# nrf9220_cellrf register map
Vendor: Nordic Semiconductor; Series: nRF92; File version: 1
CPU: CM0 r0p0, little endian, no MPU, no FPU, 2 interrupt priority bits, 33 interrupts
Registers are 32-bit, read-write, reset 0x0 unless marked. A register's access mark holds for its fields unless they carry their own. Offsets are from the block's base; [hi:lo] are bit positions; {n}, {i} and the like mark numbered series; 'fields as' and 'values as' point back to an identical list.

## TXDFE — HALTI_TX_register_map AhmaTxDigDigitalReg register map KarhuTxDigAnalogReg register map
Base 0x46120000
0x00 TASKS_TX_START_DIG wo — Starts TX digital core.
  [0] TASKS_TX_START_DIG
    1=Trigger task
0x04 TASKS_TX_STOP_DIG wo — Stops TX digital core.
  [0] TASKS_TX_STOP_DIG
    1=Trigger task
0x08 TASKS_TX_COMPARATOR wo — Reset comparator status register
  [0] TASKS_TX_COMPARATOR
    1=Trigger task
0x0C TASKS_TX_SATURATION_HOLD wo — Reset saturation hold
  [0] TASKS_TX_SATURATION_HOLD
    1=Trigger task
0x10 TASKS_TX_CLEAR_UNDERFLOW wo — Clear FIFO underflow bit
  [0] TASKS_TX_CLEAR_UNDERFLOW
    1=Trigger task
0x14 TASKS_TX_CAPT_SAMPLE_CNT wo — Capture sample counter value to register
  [0] TASKS_TX_CAPT_SAMPLE_CNT
    1=Trigger task
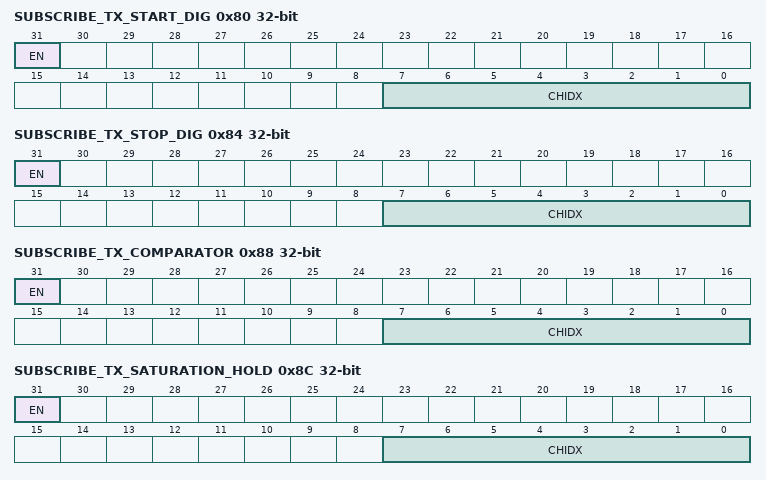
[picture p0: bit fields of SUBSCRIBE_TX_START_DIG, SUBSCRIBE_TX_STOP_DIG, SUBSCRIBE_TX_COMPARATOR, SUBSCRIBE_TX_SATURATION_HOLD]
0x80 SUBSCRIBE_TX_START_DIG — Subscribe configuration for task TX_START_DIG
  [31] EN
    0=Disabled (Disable subscription); 1=Enabled (Enable subscription)
  [7:0] CHIDX — DPPI channel that task TX_START_DIG will subscribe to
0x84 SUBSCRIBE_TX_STOP_DIG — Subscribe configuration for task TX_STOP_DIG
  [31] EN
    values as SUBSCRIBE_TX_START_DIG.EN
  [7:0] CHIDX — DPPI channel that task TX_STOP_DIG will subscribe to
0x88 SUBSCRIBE_TX_COMPARATOR — Subscribe configuration for task TX_COMPARATOR
  [31] EN
    values as SUBSCRIBE_TX_START_DIG.EN
  [7:0] CHIDX — DPPI channel that task TX_COMPARATOR will subscribe to
0x8C SUBSCRIBE_TX_SATURATION_HOLD — Subscribe configuration for task TX_SATURATION_HOLD
  [31] EN
    values as SUBSCRIBE_TX_START_DIG.EN
  [7:0] CHIDX — DPPI channel that task TX_SATURATION_HOLD will subscribe to
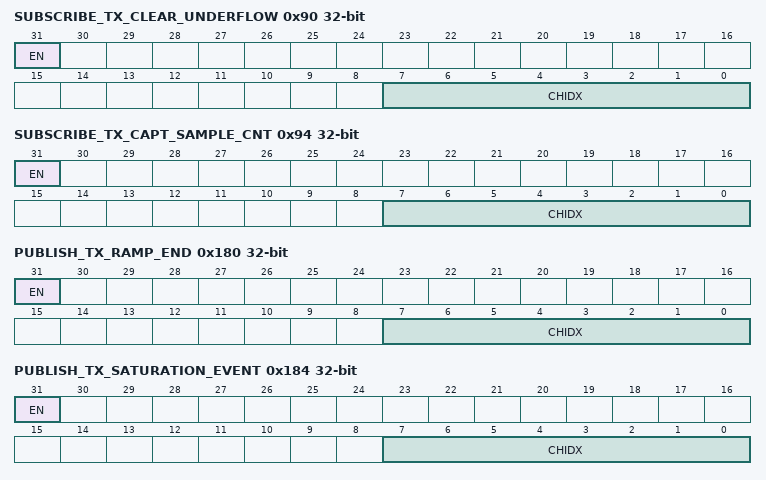
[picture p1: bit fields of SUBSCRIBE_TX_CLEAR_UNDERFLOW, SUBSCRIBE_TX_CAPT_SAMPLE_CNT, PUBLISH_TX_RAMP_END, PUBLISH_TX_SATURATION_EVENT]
0x90 SUBSCRIBE_TX_CLEAR_UNDERFLOW — Subscribe configuration for task TX_CLEAR_UNDERFLOW
  [31] EN
    values as SUBSCRIBE_TX_START_DIG.EN
  [7:0] CHIDX — DPPI channel that task TX_CLEAR_UNDERFLOW will subscribe to
0x94 SUBSCRIBE_TX_CAPT_SAMPLE_CNT — Subscribe configuration for task TX_CAPT_SAMPLE_CNT
  [31] EN
    values as SUBSCRIBE_TX_START_DIG.EN
  [7:0] CHIDX — DPPI channel that task TX_CAPT_SAMPLE_CNT will subscribe to
0x100 EVENTS_TX_RAMP_END — Ramp generator reached end.
  [0] EVENTS_TX_RAMP_END
    0=NotGenerated (Event not generated); 1=Generated (Event generated)
0x104 EVENTS_TX_SATURATION_EVENT — Indicates when saturation is occurred
  [0] EVENTS_TX_SATURATION_EVENT
    values as EVENTS_TX_RAMP_END.EVENTS_TX_RAMP_END
0x108 EVENTS_TX_SATURATION_EVENT_N — Indicates when saturation is ended
  [0] EVENTS_TX_SATURATION_EVENT_N
    values as EVENTS_TX_RAMP_END.EVENTS_TX_RAMP_END
0x10C EVENTS_TX_FIFO_UNDERFLOW — Indicates if FIFO goes to underflow state
  [0] EVENTS_TX_FIFO_UNDERFLOW
    values as EVENTS_TX_RAMP_END.EVENTS_TX_RAMP_END
0x180 PUBLISH_TX_RAMP_END — Publish configuration for event TX_RAMP_END
  [31] EN
    0=Disabled (Disable publishing); 1=Enabled (Enable publishing)
  [7:0] CHIDX — DPPI channel that event TX_RAMP_END will publish to
0x184 PUBLISH_TX_SATURATION_EVENT — Publish configuration for event TX_SATURATION_EVENT
  [31] EN
    values as PUBLISH_TX_RAMP_END.EN
  [7:0] CHIDX — DPPI channel that event TX_SATURATION_EVENT will publish to
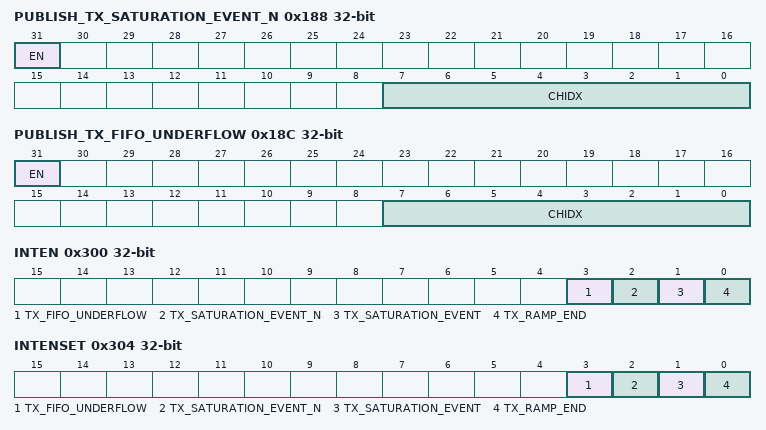
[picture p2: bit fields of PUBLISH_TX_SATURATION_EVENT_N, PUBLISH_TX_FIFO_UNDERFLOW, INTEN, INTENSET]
0x188 PUBLISH_TX_SATURATION_EVENT_N — Publish configuration for event TX_SATURATION_EVENT_N
  [31] EN
    values as PUBLISH_TX_RAMP_END.EN
  [7:0] CHIDX — DPPI channel that event TX_SATURATION_EVENT_N will publish to
0x18C PUBLISH_TX_FIFO_UNDERFLOW — Publish configuration for event TX_FIFO_UNDERFLOW
  [31] EN
    values as PUBLISH_TX_RAMP_END.EN
  [7:0] CHIDX — DPPI channel that event TX_FIFO_UNDERFLOW will publish to
0x300 INTEN — Enable or disable interrupt
  [all] fields
    0=Disabled; 1=Enabled
  [3] TX_FIFO_UNDERFLOW — Enable or disable interrupt for event TX_FIFO_UNDERFLOW
  [2] TX_SATURATION_EVENT_N — Enable or disable interrupt for event TX_SATURATION_EVENT_N
  [1] TX_SATURATION_EVENT — Enable or disable interrupt for event TX_SATURATION_EVENT
  [0] TX_RAMP_END — Enable or disable interrupt for event TX_RAMP_END
0x304 INTENSET — Enable interrupt
  [all] fields
    on read: 0=Disabled (Read: Disabled); 1=Enabled (Read: Enabled) | on write: 1=Set (Enable)
  [3] TX_FIFO_UNDERFLOW — Write '1' to enable interrupt for event TX_FIFO_UNDERFLOW
  [2] TX_SATURATION_EVENT_N — Write '1' to enable interrupt for event TX_SATURATION_EVENT_N
  [1] TX_SATURATION_EVENT — Write '1' to enable interrupt for event TX_SATURATION_EVENT
  [0] TX_RAMP_END — Write '1' to enable interrupt for event TX_RAMP_END
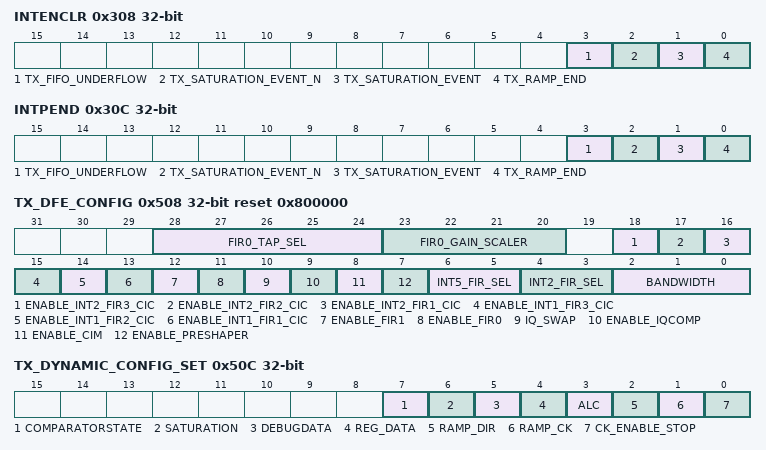
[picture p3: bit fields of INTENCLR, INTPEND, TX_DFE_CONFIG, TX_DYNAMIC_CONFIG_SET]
0x308 INTENCLR — Disable interrupt
  [all] fields
    on read: 0=Disabled (Read: Disabled); 1=Enabled (Read: Enabled) | on write: 1=Clear (Disable)
  [3] TX_FIFO_UNDERFLOW — Write '1' to disable interrupt for event TX_FIFO_UNDERFLOW
  [2] TX_SATURATION_EVENT_N — Write '1' to disable interrupt for event TX_SATURATION_EVENT_N
  [1] TX_SATURATION_EVENT — Write '1' to disable interrupt for event TX_SATURATION_EVENT
  [0] TX_RAMP_END — Write '1' to disable interrupt for event TX_RAMP_END
0x30C INTPEND ro — Pending interrupts
  [all] fields
    on read: 0=NotPending (Read: Not pending); 1=Pending (Read: Pending)
  [3] TX_FIFO_UNDERFLOW — Read pending status of interrupt for event TX_FIFO_UNDERFLOW
  [2] TX_SATURATION_EVENT_N — Read pending status of interrupt for event TX_SATURATION_EVENT_N
  [1] TX_SATURATION_EVENT — Read pending status of interrupt for event TX_SATURATION_EVENT
  [0] TX_RAMP_END — Read pending status of interrupt for event TX_RAMP_END
0x500 TX_DIG_ENABLE — TX digital enable
  [0] ENABLE — Enable TX digital. When enabled the task TASKS_TX_DIG_START can be used to activate TX digital.
    0=Disabled; 1=Enabled
0x504 TX_FIFO_ENABLE
  [0] ENABLE — Enable TX FIFO. When enabled the task TASKS_TX_FIFO_START can be used to activate TX FIFO.
    0=Disabled; 1=Enabled
0x508 TX_DFE_CONFIG reset 0x800000 — TX DFE datapath configuration
  [28:24] FIR0_TAP_SEL — Selects how many taps there is in use in FIR0. 2-28 will give corresponding numbers of taps. Other values will take all taps into use.
  [23:20] FIR0_GAIN_SCALER — Gain scaling after FIR0. Number indicates how many times data value is shifted to right after FIR0.
  [18] ENABLE_INT2_FIR3_CIC — Enable or disable first CIC after INT2FIR3
    0=Disabled; 1=Enabled
  [17] ENABLE_INT2_FIR2_CIC — Enable or disable first CIC after INT2FIR2
    0=Disabled; 1=Enabled
  [16] ENABLE_INT2_FIR1_CIC — Enable or disable first CIC after INT2FIR1
    0=Disabled; 1=Enabled
  [15] ENABLE_INT1_FIR3_CIC — Enable or disable first CIC after INT1FIR3
    0=Disabled; 1=Enabled
  [14] ENABLE_INT1_FIR2_CIC — Enable or disable first CIC after INT1FIR2
    0=Disabled; 1=Enabled
  [13] ENABLE_INT1_FIR1_CIC — Enable or disable first CIC after INT1FIR1
    0=Disabled; 1=Enabled
  [12] ENABLE_FIR1 — Enable or disable second configurable FIR.
    0=Disabled; 1=Enabled
  [11] ENABLE_FIR0 — Enable or disable first configurable FIR.
    0=Disabled; 1=Enabled
  [10] IQ_SWAP — I and Q branches are swapped at the input.
    0=Disabled; 1=Enabled
  [9] ENABLE_IQCOMP — IQ compensation enabled in TX datapath.
    0=Disabled; 1=Enabled
  [8] ENABLE_CIM — CIM enabled in TX datapath.
    0=Disabled; 1=Enabled
  [7] ENABLE_PRESHAPER — Preshaper enabled in TX datapath.
    0=Disabled; 1=Enabled
  [6:5] INT5_FIR_SEL — Select last interpolation filter
    0=Disabled (Filter is bypassed); 1=Narrow passband in filter, gives better performance with lower frequencies. Normalized 1 dB cutoff at 0.027 (fs/2); 2=Wider passband in filter. Normalized 1 dB cutoff at 0.10 (fs/2); 3=Auto (5x interpolation filter is selected automatically depending on bandwidth)
  [4:3] INT2_FIR_SEL — Select number of 2x interpolation filters in datapath
    0=x4 (No INT2 filters added to default x4 datapath); 1=x8 (One INT2 filter added to default datapath (x8, LTE5)); 2=x16 (Two INT2 filters added to datapath (x16, LTE3)); 3=x32 (Three INT2 filters added to datapath (x32, LTE1.4 and NB1))
  [2:0] BANDWIDTH — Bandwidth selection.
    0=div160 (Input sample rate is ckDac/160 (1.92 MHz used by LTE 1.4 and NB1)); 1=div80 (Input sample rate is ckDac/80 (3.84 MHz, used by LTE 3)); 2=div40 (Input sample rate is ckDac/40 (7.68 MHz, used by LTE 5)); 3=div20 (Input sample rate is ckDac/20 (13.824 MHz, used by DECT)); 4=div10 (Input sample rate is ckDac/10 (30.72 MHz))
0x50C TX_DYNAMIC_CONFIG_SET write-1-sets — TX DFE dynamic module enabling
  [7] COMPARATORSTATE — Enable comparator state change tracking.
    0=NoEffect; 1=Activate
  [6] SATURATION — Enable saturation indicators from core.
    0=NoEffect; 1=Activate
  [5] DEBUGDATA — Enable interleaved data to debug mux.
    0=NoEffect; 1=Activate
  [4] REG_DATA — Data is feed from register to DAC.
    0=NoEffect; 1=Activate
  [3] ALC — Enable gain control in TX datapath
    0=NoEffect; 1=Activate
  [2] RAMP_DIR — Set ramp direction to up
    0=NoEffect; 1=Up (Ramp runs from minimum to maximum.)
  [1] RAMP_CK — Clock for ramping enabled.
    0=NoEffect; 1=Activate
  [0] CK_ENABLE_STOP — Stops clock enabling from TX datapath.
    0=NoEffect; 1=Activate
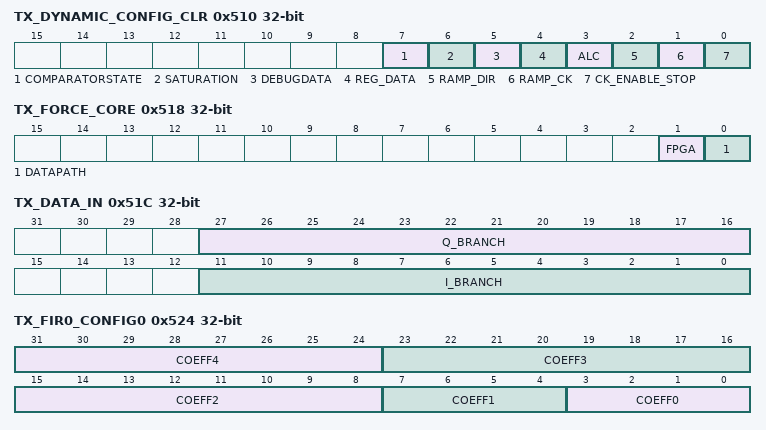
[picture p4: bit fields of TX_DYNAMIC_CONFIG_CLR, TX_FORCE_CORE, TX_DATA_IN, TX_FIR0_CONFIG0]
0x510 TX_DYNAMIC_CONFIG_CLR write-1-clears — TX DFE dynamic module disabling
  [7] COMPARATORSTATE — Disable comparator state change tracking.
    0=NoEffect; 1=Disable
  [6] SATURATION — Disable saturation indicators from core.
    0=NoEffect; 1=Disable
  [5] DEBUGDATA — Disable interleaved data to debug mux.
    0=NoEffect; 1=Disable
  [4] REG_DATA — Normal data input in use.
    0=NoEffect; 1=Disable
  [3] ALC — Disable gain control in TX datapath
    0=NoEffect; 1=Disable
  [2] RAMP_DIR — Set ramp direction to down
    0=NoEffect; 1=Down (Ramp runs from maximum to minimum.)
  [1] RAMP_CK — Clock for ramping disabled.
    0=NoEffect; 1=Disable
  [0] CK_ENABLE_STOP — Clock enabling activated for TX datapath.
    0=NoEffect; 1=Disable
0x514 TX_DAC_CK_REQ — TX ADC clock request
  [0] REQ — Requests DAC clock.
    0=NoRequest; 1=Request
0x518 TX_FORCE_CORE — TX digital clock forcing
  [1] FPGA — Clock for FPGA tester forced on.
    0=Disabled; 1=Enabled
  [0] DATAPATH — Enable datapath clock forcing.
    0=Disabled; 1=Enabled
0x51C TX_DATA_IN — Data register for I and Q for DAC
  [27:16] Q_BRANCH — Q data input for DAC, signed 12 bits.
  [11:0] I_BRANCH — I data input for DAC, signed 12 bits.
0x520 TX_DIG_SPARE — Spare bits
  [15:0] SPARE — Spare bits.
0x524 TX_FIR0_CONFIG0 — FIR 0 coefficient set 0
  [31:24] COEFF4 — Coefficient 4 for first FIR.
  [23:16] COEFF3 — Coefficient 3 for first FIR.
  [15:8] COEFF2 — Coefficient 2 for first FIR.
  [7:4] COEFF1 — Coefficient 1 for first FIR.
  [3:0] COEFF0 — Coefficient 0 for first FIR.
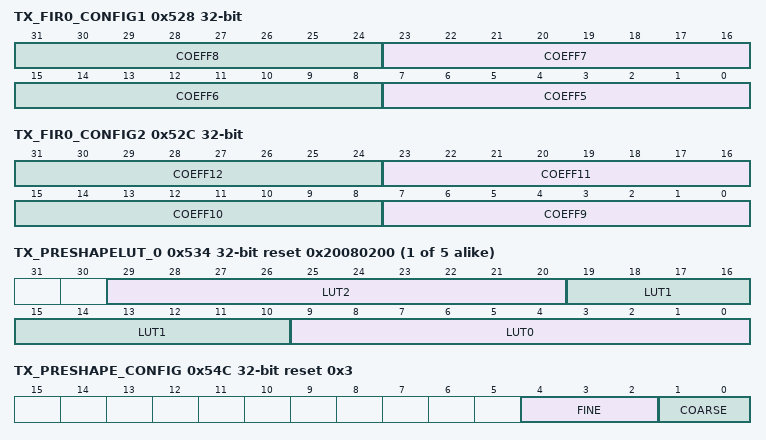
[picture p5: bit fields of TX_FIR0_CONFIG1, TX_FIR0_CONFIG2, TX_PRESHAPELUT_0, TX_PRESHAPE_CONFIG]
0x528 TX_FIR0_CONFIG1 — FIR 0 coefficient set 1
  [8n-33:8n-40] COEFF{n} (n=5..8) — Coefficient {n} for first FIR.
0x52C TX_FIR0_CONFIG2 — FIR 0 coefficient set 2
  [8n-65:8n-72] COEFF{n} (n=9..12) — Coefficient {n} for first FIR.
0x530 TX_FIR0_CONFIG3 — FIR 0 coefficient set 3
  [8:0] COEFF13 — Coefficient 13 for first FIR.
{0x534+4i} TX_PRESHAPELUT_{i} reset 0x20080200 (i=0..4) — Preshaper LUT values for indexes {3i}, {3i+1} and {3i+2}.
  [29:20] LUT{3i+2} — LUT index {3i+2} value in preshaper.
  [19:10] LUT{3i+1} — LUT index {3i+1} value in preshaper.
  [9:0] LUT{3i} — LUT index {3i} value in preshaper.
0x548 TX_PRESHAPELUT_5 reset 0x200 — Preshaper LUT values for index 15.
  [9:0] LUT15 — LUT index 15 value in preshaper.
0x54C TX_PRESHAPE_CONFIG reset 0x3 — Power scaling in preshaper for matching whole LUT table.
  [4:2] FINE — Fine gain for preshaper scaler.
  [1:0] COARSE — Coarse gain for preshaper scaler.
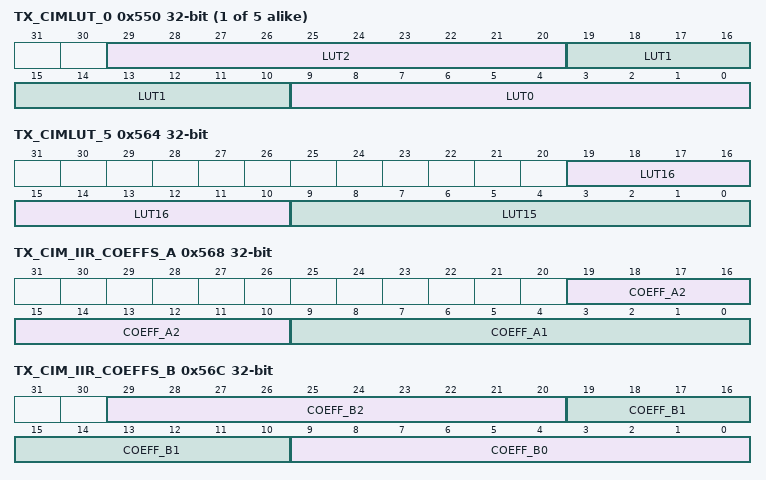
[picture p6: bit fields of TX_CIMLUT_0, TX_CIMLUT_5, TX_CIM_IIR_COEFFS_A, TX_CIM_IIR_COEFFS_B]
{0x550+4i} TX_CIMLUT_{i} (i=0..4) — CIM LUT values for indexes {3i}, {3i+1} and {3i+2}.
  [29:20] LUT{3i+2} — 10 bits unsigned LUT index {3i+2} value in CIM.
  [19:10] LUT{3i+1} — 10 bits unsigned LUT index {3i+1} value in CIM.
  [9:0] LUT{3i} — 10 bits unsigned LUT index {3i} value in CIM.
0x564 TX_CIMLUT_5 — CIM LUT values for indexes 15 and 16.
  [19:10] LUT16 — 10 bits unsigned LUT index 16 value in CIM.
  [9:0] LUT15 — 10 bits unsigned LUT index 15 value in CIM.
0x568 TX_CIM_IIR_COEFFS_A — Coefficients for CIM IIR denominator.
  [19:10] COEFF_A2 — IIR coefficient A2.
  [9:0] COEFF_A1 — IIR coefficient A1.
0x56C TX_CIM_IIR_COEFFS_B — Coefficients for CIM IIR numerator.
  [29:20] COEFF_B2 — IIR coefficient B2.
  [19:10] COEFF_B1 — IIR coefficient B1.
  [9:0] COEFF_B0 — IIR coefficient B0.
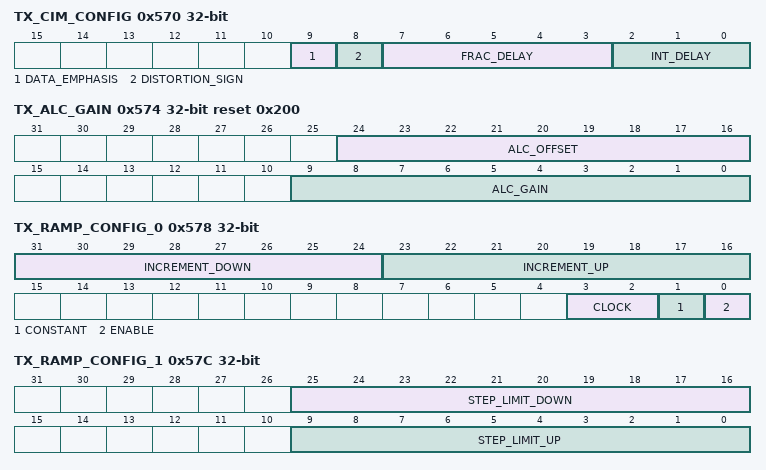
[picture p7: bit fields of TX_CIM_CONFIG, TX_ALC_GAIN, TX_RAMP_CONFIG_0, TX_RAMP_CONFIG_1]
0x570 TX_CIM_CONFIG — CIM configuration bits.
  [9] DATA_EMPHASIS — Determines when distortion is added to data.
    0=Disabled (Distortion added after IIR filtering.); 1=Enabled (Distortion added before IIR filtering.)
  [8] DISTORTION_SIGN — Sign of distortion when added to data (causes phase shift of 180).
    0=Minus (Distortion is subtracted from data.); 1=Plus (Distortion is added to data.)
  [7:3] FRAC_DELAY — Fractional delay in distortion path.
  [2:0] INT_DELAY — Integer delay in distortion path.
0x574 TX_ALC_GAIN reset 0x200 — ALC gain settings.
  [24:16] ALC_OFFSET — Gain offset.
  [9:0] ALC_GAIN — Gain value.
0x578 TX_RAMP_CONFIG_0 — RampGenerator related configurations.
  [31:24] INCREMENT_DOWN — Step increment value down direction.
  [23:16] INCREMENT_UP — Step increment value up direction.
  [3:2] CLOCK — Selects frequency used in ramp.
    0=div20 (ckDac/20 (15.36 MHz in LTE)); 1=div10 (ckDac/10 (30.72 MHz in LTE)); 2=div5 (ckDac/5 (61.44 MHz in LTE)); 3=div40 (ckDac/40 (7.68 MHz in LTE))
  [1] CONSTANT — Enables constant step change.
    0=Disabled; 1=Enabled
  [0] ENABLE — Gates ramp value entering to ALC part of design.
    0=Disabled; 1=Enabled
0x57C TX_RAMP_CONFIG_1 — RampGenerator related configurations.
  [25:16] STEP_LIMIT_DOWN — Stepper turning point down direction.
  [9:0] STEP_LIMIT_UP — Stepper turning point up direction.
0x580 TX_RAMP_STATE ro — Ramp end indicator.
  [0] END — Indicates when ramp has reached its end.
    0=Running (Ramp is running.); 1=End (Ramp is reached maximum or minimum value.)
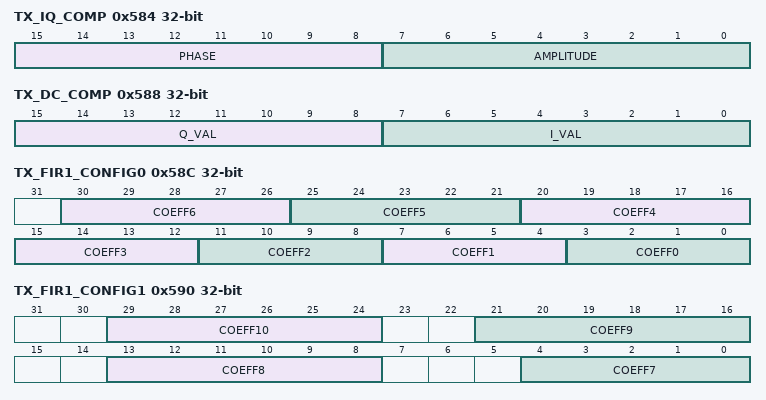
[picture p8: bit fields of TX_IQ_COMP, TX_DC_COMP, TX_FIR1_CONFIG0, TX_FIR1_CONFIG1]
0x584 TX_IQ_COMP — IQ amplitude and phase compensation value.
  [15:8] PHASE — IQ compensation value for phase.
  [7:0] AMPLITUDE — IQ compensation value for amplitude.
0x588 TX_DC_COMP — FIR 2 coefficients 12, 13, 14 and 15.
  [15:8] Q_VAL — DC compensation value for Q branch.
  [7:0] I_VAL — DC compensation value for I branch.
0x58C TX_FIR1_CONFIG0 — FIR 1 coefficient set 0
  [30:26] COEFF6 — Coefficient 6 for second FIR.
  [25:21] COEFF5 — Coefficient 5 for second FIR.
  [20:16] COEFF4 — Coefficient 4 for second FIR.
  [4n+3:4n] COEFF{n} (n=0..3) — Coefficient {n} for second FIR.
0x590 TX_FIR1_CONFIG1 — FIR 1 coefficient set 0
  [29:24] COEFF10 — Coefficient 10 for second FIR.
  [21:16] COEFF9 — Coefficient 9 for second FIR.
  [13:8] COEFF8 — Coefficient 8 for second FIR.
  [4:0] COEFF7 — Coefficient 7 for second FIR.
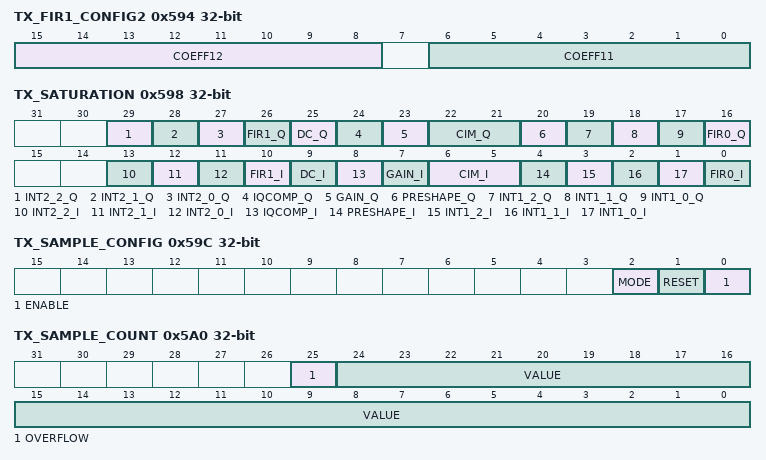
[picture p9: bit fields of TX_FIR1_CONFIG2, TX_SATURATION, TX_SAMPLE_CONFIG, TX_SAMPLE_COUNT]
0x594 TX_FIR1_CONFIG2 — FIR 1 coefficient set 2
  [15:8] COEFF12 — Coefficient 12 for second FIR.
  [6:0] COEFF11 — Coefficient 11 for second FIR.
0x598 TX_SATURATION ro — Saturation indication bits.
  [all] fields
    0=No_saturation (Not detected); 1=Saturation_detected (Detected)
  [29] INT2_2_Q — Saturation indicator.
  [28] INT2_1_Q — Saturation indicator.
  [27] INT2_0_Q — Saturation indicator.
  [26] FIR1_Q — Saturation indicator.
  [25] DC_Q — Saturation indicator.
  [24] IQCOMP_Q — Saturation indicator.
  [23] GAIN_Q — Saturation indicator.
  [22:21] CIM_Q — Saturation indicator.
  [20] PRESHAPE_Q — Saturation indicator.
  [19] INT1_2_Q — Saturation indicator.
  [18] INT1_1_Q — Saturation indicator.
  [17] INT1_0_Q — Saturation indicator.
  [16] FIR0_Q — Saturation indicator.
  [13] INT2_2_I — Saturation indicator.
  [12] INT2_1_I — Saturation indicator.
  [11] INT2_0_I — Saturation indicator.
  [10] FIR1_I — Saturation indicator.
  [9] DC_I — Saturation indicator.
  [8] IQCOMP_I — Saturation indicator.
  [7] GAIN_I — Saturation indicator.
  [6:5] CIM_I — Saturation indicator.
  [4] PRESHAPE_I — Saturation indicator.
  [3] INT1_2_I — Saturation indicator.
  [2] INT1_1_I — Saturation indicator.
  [1] INT1_0_I — Saturation indicator.
  [0] FIR0_I — Saturation indicator.
0x59C TX_SAMPLE_CONFIG — Sample counter value
  [2] MODE — Sample counter mode.
    0=Synchronized, counter value is set to 0 when TX digital is activated; 1=Free, counter value is not set to 0 when TX digital is activated
  [1] RESET — Sample counter reset.
    0=Disabled; 1=Enabled
  [0] ENABLE — Sample counter enable.
    0=Disabled; 1=Enabled
0x5A0 TX_SAMPLE_COUNT ro — Sample counter value
  [25] OVERFLOW — Sample counter overflow indicator.
  [24:0] VALUE — Sample counter value.
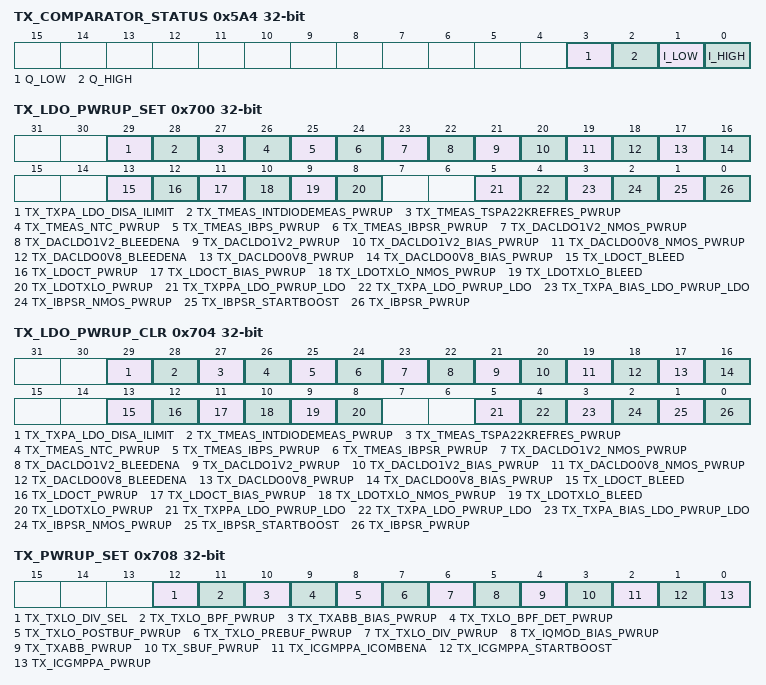
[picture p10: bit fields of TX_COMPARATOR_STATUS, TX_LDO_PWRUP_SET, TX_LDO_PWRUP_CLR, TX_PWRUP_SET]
0x5A4 TX_COMPARATOR_STATUS ro — Comparator state changes
  [3] Q_LOW — Captures Q branch change to low.
    0=Undetected (Comparator Q not low); 1=Detected (Comparator Q low detected)
  [2] Q_HIGH — Captures Q branch change to high.
    0=Undetected (Comparator Q not high); 1=Detected (Comparator Q high detected)
  [1] I_LOW — Captures I branch change to low.
    0=Undetected (Comparator I not low); 1=Detected (Comparator I low detected)
  [0] I_HIGH — Captures I branch change to high.
    0=Undetected (Comparator I not high); 1=Detected (Comparator I high detected)
{0x5B0+4i} TX_DEBUG_{i}_PSEL (i=0..7) — TX debug {i} port/pin selection.
  [3:0] SELECT — Connection selection.
0x700 TX_LDO_PWRUP_SET write-1-sets — TX LDO power power up register
  [all] fields
    1=activate (Unspecified); 0=no_effect (Unspecified)
  [29] TX_TXPA_LDO_DISA_ILIMIT — PA LDO ILIM DISABLE
  [28] TX_TMEAS_INTDIODEMEAS_PWRUP — TMEAS INTDIODE power up
  [27] TX_TMEAS_TSPA22KREFRES_PWRUP — TMEAS TSPA
  [26] TX_TMEAS_NTC_PWRUP — TMEAS NTC power up
  [25] TX_TMEAS_IBPS_PWRUP — TMEAS IBPS power up
  [24] TX_TMEAS_IBPSR_PWRUP — TMEAS IBPSR power up
  [23] TX_DACLDO1V2_NMOS_PWRUP — LDO NMOS cascade high PSRR
  [22] TX_DACLDO1V2_BLEEDENA — LDO bleed active
  [21] TX_DACLDO1V2_PWRUP — LDO power up
  [20] TX_DACLDO1V2_BIAS_PWRUP — LDO bias power up
  [19] TX_DACLDO0V8_NMOS_PWRUP — LDO NMOS cascade high PSRR
  [18] TX_DACLDO0V8_BLEEDENA — LDO bleed active
  [17] TX_DACLDO0V8_PWRUP — LDO power up
  [16] TX_DACLDO0V8_BIAS_PWRUP — LDO bias power up
  [13] TX_LDOCT_BLEED — LDO bleed active
  [12] TX_LDOCT_PWRUP — LDO power up
  [11] TX_LDOCT_BIAS_PWRUP — LDO bias power up
  [10] TX_LDOTXLO_NMOS_PWRUP — LDO NMOS cascade high PSRR
  [9] TX_LDOTXLO_BLEED — LDO bleed active
  [8] TX_LDOTXLO_PWRUP — LDO power up
  [5] TX_TXPPA_LDO_PWRUP_LDO — PPA LDO PWRUP
  [4] TX_TXPA_LDO_PWRUP_LDO — PA LDO PWRUP
  [3] TX_TXPA_BIAS_LDO_PWRUP_LDO — PA BIAS LDO PWRUP
  [2] TX_IBPSR_NMOS_PWRUP — IBPSR NMOS cascade high PSRR
  [1] TX_IBPSR_STARTBOOST — IBPSR startboost
  [0] TX_IBPSR_PWRUP — IBPSR power up
0x704 TX_LDO_PWRUP_CLR write-1-clears — TXLDO power power down register
  [all] fields
    1=disable (Unspecified); 0=no_effect (Unspecified)
  [29] TX_TXPA_LDO_DISA_ILIMIT — PA LDO ILIM DISABLE
  [28] TX_TMEAS_INTDIODEMEAS_PWRUP — TMEAS INTDIODE power up
  [27] TX_TMEAS_TSPA22KREFRES_PWRUP — TMEAS TSPA
  [26] TX_TMEAS_NTC_PWRUP — TMEAS NTC power up
  [25] TX_TMEAS_IBPS_PWRUP — TMEAS IBPS power up
  [24] TX_TMEAS_IBPSR_PWRUP — TMEAS IBPSR power up
  [23] TX_DACLDO1V2_NMOS_PWRUP — LDO NMOS cascade high PSRR
  [22] TX_DACLDO1V2_BLEEDENA — LDO bleed active
  [21] TX_DACLDO1V2_PWRUP — LDO power up
  [20] TX_DACLDO1V2_BIAS_PWRUP — LDO bias power up
  [19] TX_DACLDO0V8_NMOS_PWRUP — LDO NMOS cascade high PSRR
  [18] TX_DACLDO0V8_BLEEDENA — LDO bleed active
  [17] TX_DACLDO0V8_PWRUP — LDO power up
  [16] TX_DACLDO0V8_BIAS_PWRUP — LDO bias power up
  [13] TX_LDOCT_BLEED — LDO bleed active
  [12] TX_LDOCT_PWRUP — LDO power up
  [11] TX_LDOCT_BIAS_PWRUP — LDO bias power up
  [10] TX_LDOTXLO_NMOS_PWRUP — LDO NMOS cascade high PSRR
  [9] TX_LDOTXLO_BLEED — LDO bleed active
  [8] TX_LDOTXLO_PWRUP — LDO power up
  [5] TX_TXPPA_LDO_PWRUP_LDO — PPA LDO PWRUP
  [4] TX_TXPA_LDO_PWRUP_LDO — PA LDO PWRUP
  [3] TX_TXPA_BIAS_LDO_PWRUP_LDO — PA BIAS LDO PWRUP
  [2] TX_IBPSR_NMOS_PWRUP — IBPSR NMOS cascade high PSRR
  [1] TX_IBPSR_STARTBOOST — IBPSR startboost
  [0] TX_IBPSR_PWRUP — IBPSR power up
0x708 TX_PWRUP_SET write-1-sets — TX power up register
  [all] fields
    1=activate (Unspecified); 0=no_effect (Unspecified)
  [12] TX_TXLO_DIV_SEL — Power up
  [11] TX_TXLO_BPF_PWRUP — Power up
  [10] TX_TXABB_BIAS_PWRUP — Power up
  [9] TX_TXLO_BPF_DET_PWRUP — Power up
  [8] TX_TXLO_POSTBUF_PWRUP — Power up
  [7] TX_TXLO_PREBUF_PWRUP — Power up
  [6] TX_TXLO_DIV_PWRUP — Power up
  [5] TX_IQMOD_BIAS_PWRUP — Power up
  [4] TX_TXABB_PWRUP — Power up
  [3] TX_SBUF_PWRUP — Power up
  [2] TX_ICGMPPA_ICOMBENA — Power up
  [1] TX_ICGMPPA_STARTBOOST — Power up
  [0] TX_ICGMPPA_PWRUP — Power up
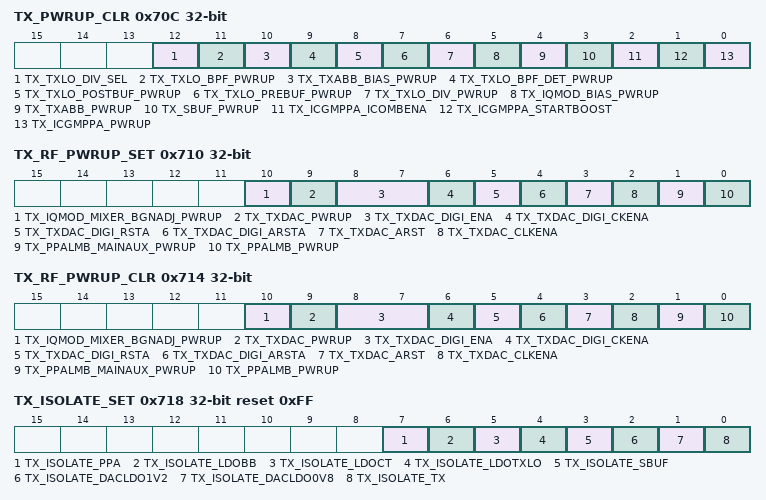
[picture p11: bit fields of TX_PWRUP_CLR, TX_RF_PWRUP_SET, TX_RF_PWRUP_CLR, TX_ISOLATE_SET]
0x70C TX_PWRUP_CLR write-1-clears — TX power down register
  [all] fields
    1=disable (Unspecified); 0=no_effect (Unspecified)
  [12] TX_TXLO_DIV_SEL — Power down
  [11] TX_TXLO_BPF_PWRUP — Power down
  [10] TX_TXABB_BIAS_PWRUP — Power down
  [9] TX_TXLO_BPF_DET_PWRUP — Power down
  [8] TX_TXLO_POSTBUF_PWRUP — Power down
  [7] TX_TXLO_PREBUF_PWRUP — Power down
  [6] TX_TXLO_DIV_PWRUP — Power down
  [5] TX_IQMOD_BIAS_PWRUP — Power down
  [4] TX_TXABB_PWRUP — Power down
  [3] TX_SBUF_PWRUP — Power down
  [2] TX_ICGMPPA_ICOMBENA — Power down
  [1] TX_ICGMPPA_STARTBOOST — Power down
  [0] TX_ICGMPPA_PWRUP — Power down
0x710 TX_RF_PWRUP_SET write-1-sets — TXPPA power up register
  [10] TX_IQMOD_MIXER_BGNADJ_PWRUP — Power up
    1=activate (Unspecified); 0=no_effect (Unspecified)
  [9] TX_TXDAC_PWRUP — Power up
    1=activate (Unspecified); 0=no_effect (Unspecified)
  [8:7] TX_TXDAC_DIGI_ENA — Power up
    3=activate_IQ (Unspecified); 2=activate_Q (Unspecified); 1=activate_I (Unspecified); 0=no_effect (Unspecified)
  [6] TX_TXDAC_DIGI_CKENA — Power up
    1=activate (Unspecified); 0=no_effect (Unspecified)
  [5] TX_TXDAC_DIGI_RSTA — Power up
    1=activate (Unspecified); 0=no_effect (Unspecified)
  [4] TX_TXDAC_DIGI_ARSTA — Power up
    1=activate (Unspecified); 0=no_effect (Unspecified)
  [3] TX_TXDAC_ARST — Power up
    1=activate (Unspecified); 0=no_effect (Unspecified)
  [2] TX_TXDAC_CLKENA — Power up
    1=activate (Unspecified); 0=no_effect (Unspecified)
  [1] TX_PPALMB_MAINAUX_PWRUP — Power up
    1=activate (Unspecified); 0=no_effect (Unspecified)
  [0] TX_PPALMB_PWRUP — Power up
    1=activate (Unspecified); 0=no_effect (Unspecified)
0x714 TX_RF_PWRUP_CLR write-1-clears — TXPPA power down register
  [all] fields
    1=disable (Unspecified); 0=no_effect (Unspecified)
  [10] TX_IQMOD_MIXER_BGNADJ_PWRUP — Power down
  [9] TX_TXDAC_PWRUP — Power down
  [8:7] TX_TXDAC_DIGI_ENA — Power down
  [6] TX_TXDAC_DIGI_CKENA — Power down
  [5] TX_TXDAC_DIGI_RSTA — Power down
  [4] TX_TXDAC_DIGI_ARSTA — Power down
  [3] TX_TXDAC_ARST — Power down
  [2] TX_TXDAC_CLKENA — Power down
  [1] TX_PPALMB_MAINAUX_PWRUP — Power down
  [0] TX_PPALMB_PWRUP — Power down
0x718 TX_ISOLATE_SET reset 0xFF write-1-sets
  [all] fields
    1=activate (Unspecified); 0=no_effect (Unspecified)
  [7] TX_ISOLATE_PPA — Power up
  [6] TX_ISOLATE_LDOBB — Power up
  [5] TX_ISOLATE_LDOCT — Power up
  [4] TX_ISOLATE_LDOTXLO — Power up
  [3] TX_ISOLATE_SBUF — Power up
  [2] TX_ISOLATE_DACLDO1V2 — Power up
  [1] TX_ISOLATE_DACLDO0V8 — Power up
  [0] TX_ISOLATE_TX — Power up
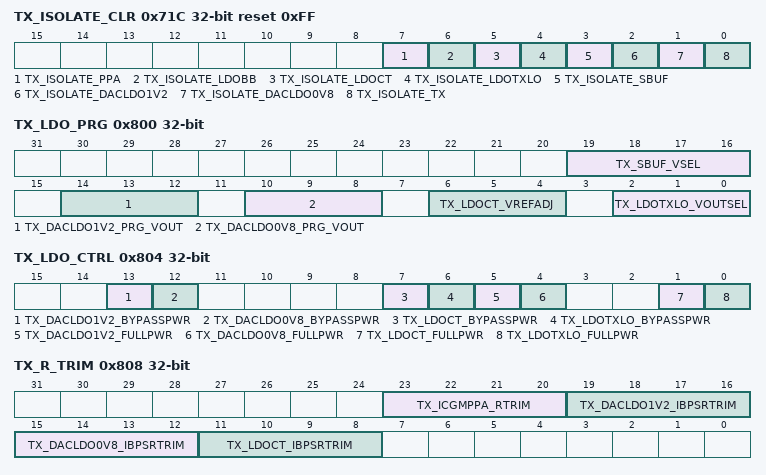
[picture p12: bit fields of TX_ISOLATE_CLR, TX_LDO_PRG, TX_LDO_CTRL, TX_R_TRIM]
0x71C TX_ISOLATE_CLR reset 0xFF write-1-clears — TX Isolate clear register
  [all] fields
    1=disable (Unspecified); 0=no_effect (Unspecified)
  [7] TX_ISOLATE_PPA — Power down
  [6] TX_ISOLATE_LDOBB — Power down
  [5] TX_ISOLATE_LDOCT — Power down
  [4] TX_ISOLATE_LDOTXLO — Power down
  [3] TX_ISOLATE_SBUF — Power down
  [2] TX_ISOLATE_DACLDO1V2 — Power down
  [1] TX_ISOLATE_DACLDO0V8 — Power down
  [0] TX_ISOLATE_TX — Power down
0x800 TX_LDO_PRG — TX LDO program
  [19:16] TX_SBUF_VSEL — SBUF output voltage selection (default 4)
    0=603mV (Unspecified); 1=653mV (Unspecified); 2=703mV (Unspecified); 3=754mV (Unspecified); 4=804mV (Unspecified); 5=829mV (Unspecified); 6=854mV (Unspecified); 7=904mV (Unspecified)
  [14:12] TX_DACLDO1V2_PRG_VOUT — LDO program (default 1)
    3=1p31V (Unspecified); 2=1p27V (Unspecified); 1=1p23V (Unspecified); 0=1p19V (Unspecified); 4=1p15V (Unspecified); 5=1p11V (Unspecified); 6=1p07V (Unspecified); 7=1p03V (Unspecified)
  [10:8] TX_DACLDO0V8_PRG_VOUT — LDO program (default 0)
    3=0p88V (Unspecified); 2=0p86V (Unspecified); 1=0p83V (Unspecified); 0=0p80V (Unspecified); 7=0p78V (Unspecified); 6=0p75V (Unspecified); 5=0p72V (Unspecified); 4=0p70V (Unspecified)
  [6:4] TX_LDOCT_VREFADJ — LDO program (default 0)
    3=1p66V (Unspecified); 2=1p61V (Unspecified); 1=1p56V (Unspecified); 0=1p51V (Unspecified); 7=1p46V (Unspecified); 6=1p41V (Unspecified); 5=1p36V (Unspecified); 4=1p31V (Unspecified)
  [2:0] TX_LDOTXLO_VOUTSEL — LDO program (default 0)
    3=900mV (Unspecified); 2=850mV (Unspecified); 1=825mV (Unspecified); 0=800mV (Unspecified); 7=750mV (Unspecified); 6=700mV (Unspecified); 5=650mV (Unspecified); 4=600mV (Unspecified)
0x804 TX_LDO_CTRL
  [13] TX_DACLDO1V2_BYPASSPWR — LDO program
    1=BypassMode (Unspecified); 0=NominalMode (Unspecified)
  [12] TX_DACLDO0V8_BYPASSPWR — LDO program
    1=BypassMode (Unspecified); 0=NominalMode (Unspecified)
  [7] TX_LDOCT_BYPASSPWR — LDO program
    1=BypassMode (Unspecified); 0=NominalMode (Unspecified)
  [6] TX_LDOTXLO_BYPASSPWR — LDO program
    1=BypassMode (Unspecified); 0=NominalMode (Unspecified)
  [5] TX_DACLDO1V2_FULLPWR — LDO program
    1=NominalOpaCurrent (Unspecified); 0=HalfOpaCurrent (Unspecified)
  [4] TX_DACLDO0V8_FULLPWR — LDO program
    values as TX_DACLDO1V2_FULLPWR
  [1] TX_LDOCT_FULLPWR — LDO program
    values as TX_DACLDO1V2_FULLPWR
  [0] TX_LDOTXLO_FULLPWR — LDO program
    values as TX_DACLDO1V2_FULLPWR
0x808 TX_R_TRIM — TX R trimming control
  [23:20] TX_ICGMPPA_RTRIM — Resistor tuning word
    0=Default (Unspecified)
  [19:16] TX_DACLDO1V2_IBPSRTRIM — Resistor tuning word
    8=Default (Unspecified)
  [15:12] TX_DACLDO0V8_IBPSRTRIM — Resistor tuning word (not used)
    8=Default (Unspecified)
  [11:8] TX_LDOCT_IBPSRTRIM — Resistor tuning word
    0=Default (Unspecified)
0x80C TX_LOBPF_C_TRIM — TX LOBPF C trimming control
  [6:0] TX_TXLO_BPF_CTUNE — TXLO BPF resonance capacitance tuning. Depends on used band
    0=max_capacitance (Minimum TXLO frequency); 127=min_capacitance (Maximum TXLO frequency)
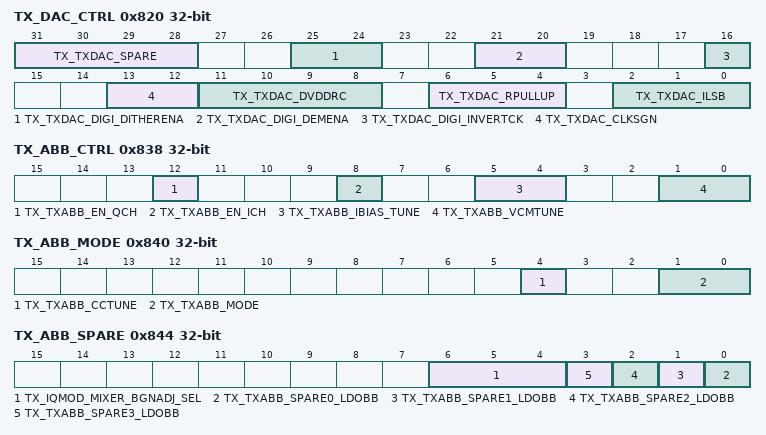
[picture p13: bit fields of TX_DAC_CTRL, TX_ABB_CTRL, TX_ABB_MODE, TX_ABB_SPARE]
0x820 TX_DAC_CTRL
  [31:28] TX_TXDAC_SPARE
  [25:24] TX_TXDAC_DIGI_DITHERENA — Dithering enable (Separate control for I and Q DACs.)
    3=Dither_enabled_IQ (Input signal LSB bits are used to dither the DEM algorithm for I+Q MSB part. Must be synchronous or set prior releasing reset.); 2=Dither_enabled_Q (Input signal LSB bits are used to dither the DEM algorithm for Q MSB part. Must be synchronous or set prior releasing reset.); 1=Dither_enabled_I (Input signal LSB bits are used to dither the DEM algorithm for I MSB part. Must be synchronous or set prior releasing reset.); 0=Dither_disabled_IQ (Dithering disabled for I and Q (default).)
  [21:20] TX_TXDAC_DIGI_DEMENA — Dynamic element matching enable (Separate control for I and Q DACs)
    3=DEM_enabled_IQ (Dynamic element matching for I+Q MSB part enabled); 2=DEM_enabled_Q (Dynamic element matching for Q MSB part enabled); 1=DEM_enabled_I (Dynamic element matching for I MSB part enabled); 0=DEM_disabled_IQ (Dynamic element matching disabled. Plain thermometer coding (default))
  [16] TX_TXDAC_DIGI_INVERTCK — Invert clock for digital island
    1=Inverted_clk (Clock is inverted. Must be synchronous or set prior releasing reset); 0=Direct_clk (Direct clock)
  [13:12] TX_TXDAC_CLKSGN — Selects if direct or inverted version of CK_TX_DAX is used inside DAC. Affects both input and output latch. Separate control for I and Q DACs.
    3=IQ_inverted (Clock phase select for DAC analog parts: I and Q inverted); 2=Q_inverted (Clock phase select for DAC analog parts: Q inverted); 1=I_inverted (Clock phase select for DAC analog parts: I inverted); 0=IQ_normal (Clock phase select for DAC analog parts: I and Q normal)
  [11:8] TX_TXDAC_DVDDRC — Bypass supply filter R
    15=min_RC (minimum RC filtering); 5=mid RC filtering; 0=max_RC (maximum RC filtering)
  [6:4] TX_TXDAC_RPULLUP — I and Q DAC pull-up resistor selection (default 4)
    7=248ohm (Unspecified); 6=271ohm (Unspecified); 5=298ohm (Unspecified); 4=331ohm (Unspecified); 3=373ohm (Unspecified); 2=426ohm (Unspecified); 1=497ohm (Unspecified); 0=596ohm (Unspecified)
  [2:0] TX_TXDAC_ILSB — I and Q DAC LSB current scaling (default 3)
    7=474nA (Unspecified); 6=446nA (Unspecified); 5=419nA (Unspecified); 4=391nA (Unspecified); 3=363nA (Unspecified); 2=335nA (Unspecified); 1=307nA (Unspecified); 0=279nA (Unspecified)
0x824 TX_DAC_TM — TX DAC test mode control
  [9:0] TX_TXDAC_TM — DAC test mode control. See Test modes section.
    0x200=Low_RL (connects extra 200 ohm resistors parallel to DAC load in order to reduce output resistance and increase the bandwidth via WATB. Both I and Q.); 0x100=Disable_IplusQ_DAC_bias (to force I and Q DAC bias off even if PWRUP =1); 128=TBD2; 64=Disable_Q_DAC_clock (to force Q DAC clock off even if CLK_EN =1); 32=Disconnect_Q_DAC_load_R (to force Q DAC load R disconnect); 16=TBD1; 8=Disable_I_DAC_clock (to force I DAC clock off even if CLK_EN =1); 4=Disconnect_I_DAC_load_R (to force I DAC load R disconnect); 2=Enable_approx_minus30_LSB (Affects both I and Q DACs); 1=Enable_approx_plus30_LSB_D (Can be used to measure DAC static linearity through nonlinear channel.); 0=active_mode (Can be used to measure DAC static linearity through nonlinear channel. Affects both I and Q DACs)
0x830 TX_ABB_GAIN — TX ABB gain selection
  [3:0] TX_TXABB_GAIN — ABB filter gain control. Controls the output signal current.
    15=3p4dB (Gain +3.4dB); 14=2p2dB (Gain +2.2dB); 13=0p8dB (Gain +0.8dB); 12=m0p9dB (Gain -0.9dB); 11=m3d0B (Gain -3.0dB); 10=m5p8dB (Gain -5.8dB); 9=m9p9dB (Gain -9.9dB); 8=m17p9dB (Gain -17.9dB); 7=4p0dB (Gain +4.0dB); 6=2p9dB (Gain +2.9dB); 5=1p5dB (Gain +1.5dB); 4=0dB (Gain 0.0dB); 3=m1p9dB (Gain -1.9dB); 2=m4p3dB (Gain -4.3dB); 1=m7p6dB (Gain -7.6dB); 0=m13p0dB (Gain -13.0dB)
0x834 TX_ABB_V2I_BIAS
  [2:0] TX_TXABB_V2I_BIAS — ABB V2I current selection. Value depends on ABB gain setting
    7=3000uA (375uA+7*375uA); 0=375uA+0*375uA
0x838 TX_ABB_CTRL — TX ABB control register
  [12] TX_TXABB_EN_QCH — ABB filter QCH enable
    0=disabled (Unspecified); 1=active (Unspecified)
  [8] TX_TXABB_EN_ICH — ABB filter ICH enable
    0=disabled (Unspecified); 1=active (Unspecified)
  [5:4] TX_TXABB_IBIAS_TUNE — ABB main bias current to IQ channel OTAs and V-I converters (default 1)
    3=30uA; 2=27p5uA (27.5uA); 1=25uA; 0=22p5uA (22.5uA)
  [1:0] TX_TXABB_VCMTUNE — ABB SF source node common mode voltage tuning in mV (default 2)
    3=425mV (Unspecified); 2=400mV (Unspecified); 1=375mV (Unspecified); 0=350mV (Unspecified)
0x83C TX_ABB_RCTUNE — TX ABB Resistor Capacitor tuning
  [4:0] TX_TXABB_FCTUNE — ABB RC constant tuning. Typ value 14dec for all other modes than LTE5
0x840 TX_ABB_MODE — TX ABB mode control register
  [4] TX_TXABB_CCTUNE — ABB filter amplifier compensation cap programming
    1=NNB_LTE1p4_WB_DECT (Unspecified); 0=NB_LTE5 (Unspecified)
  [1:0] TX_TXABB_MODE — ABB filter mode
    3=not_used (Unspecified); 2=WBmode_DECT6p912M (Unspecified); 1=NNBmode_LTE1p4_NBIoT (Unspecified); 0=NBmode_LTE5_DECT3p456M (Unspecified)
0x844 TX_ABB_SPARE — TX ABB control register
  [6:4] TX_IQMOD_MIXER_BGNADJ_SEL — IQMOD mixer back gate voltage selection (default 0)
    0=0p0V (Unspecified); 1=0p25V (Unspecified); 2=0p5V (Unspecified); 3=0p75V (Unspecified); 4=1p0V (Unspecified); 5=1p25V (Unspecified); 6=1p5V (Unspecified)
  [n] TX_TXABB_SPARE{n}_LDOBB (n=0..3) — Spare bits
0x848 TX_PPA_LDO_TRIM
  [2:0] TX_PPA_LDO_TRIM — PPA LDO output voltage trim
    0=m5p2perc (000: -5.2 percent); 1=m3p9perc; 2=m2p6perc (011: -1.3 percent); 3=m1p3perc (100: +0.0 percent (default)); 4=0perc (101: +1.3 percent); 5=1p3perc; 6=2p6perc (111: +3.9 percent); 7=3p9perc (Unspecified)
0x84C TX_PA_LDO_TRIM
  [2:0] TX_PA_LDO_TRIM — PA LDO output voltage trim
    0=0mV (011: +123mV); 1=41mV (010: +82mV); 2=82mV (001: +41mV); 3=123mV (000: 0mV (default)); 4=m164mV (111: -41mV); 5=m123mV (110: -82mV); 6=m82mV (101: -123mV); 7=m41mV (100: -164mV)
0x850 TX_PA_BIAS_LDO_TRIM
  [2:0] TX_PA_BIAS_LDO_TRIM — PA BIAS LDO output voltage trim
    0=m10p4perc (000: -10.4 percent); 1=m7p8perc; 2=m5p2perc (011: -2.6 percent); 3=m2p6perc (100: +0.0 percent (default)); 4=0perc (101: +2.6 percent); 5=2p6perc; 6=5p2perc (111: +7.8 percent); 7=7p8perc (Unspecified)
0x854 TX_PPA_LDO_PRG
  [0] TX_TXPPA_LDO_VOUT_SEL — PPA LDO out V selection
    0=1p8V (0: 1.8 V (default)); 1=1p6V (1: 1.6 V)
0x858 TX_PA_LDO_PRG
  [3:0] TX_TXPA_LDO_PRG — PA LDO out V selection
    0=1p8V (Unspecified); 8=2p8V (Unspecified); 15=4p1V (Unspecified)
0x85C TX_PA_BIAS_LDO_PRG
  [1:0] TX_TXPA_BIAS_LDO_PRG — PABIAS LDO out V selection
    0=1p8V (00: 1.8 V); 1=2p0V (01: 2.0 V (default)); 2=2p5V (10: 2.5 V); 3=3p0V (11: 3.0 V)
0x860 TX_PPA_LDO_PULLD
  [0] TX_TXPPA_LDO_PULL_DWN_N_AO — PPA LDO out V pulldown
    0=Default (Unspecified)
0x864 TX_PA_LDO_PULLD
  [0] TX_TXPA_LDO_PULL_DWN_N_AO — PA LDO out V pulldown
    0=Default (Unspecified)
0x868 TX_PA_BIAS_LDO_PULLD — TX PA PPA LDO Pulld
  [0] TX_TXPA_BIAS_LDO_PULL_DWN_N_AO — PA BIAS LDO out V pulldown
    0=Default (Unspecified)
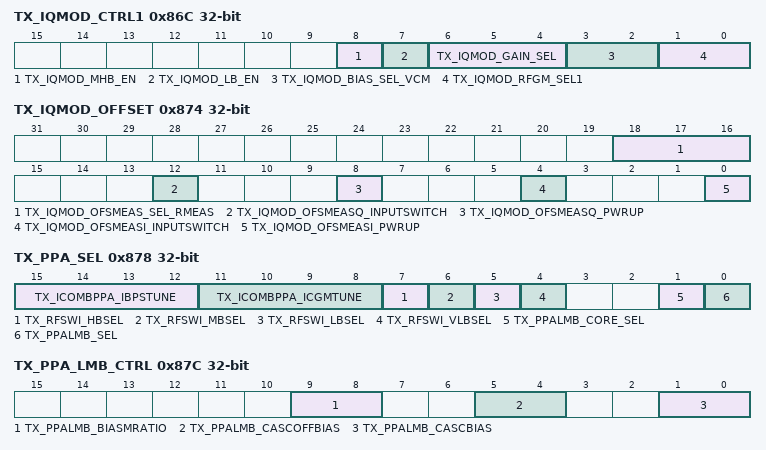
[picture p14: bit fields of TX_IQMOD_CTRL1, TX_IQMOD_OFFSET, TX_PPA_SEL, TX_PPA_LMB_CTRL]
0x86C TX_IQMOD_CTRL1 — TX IQMOD Control
  [8] TX_IQMOD_MHB_EN — IQMOD mid-band (MB) output enable
    0=disabled (Unspecified); 1=active (Unspecified)
  [7] TX_IQMOD_LB_EN — IQMOD low-band (LB) output enable
    0=disabled (Unspecified); 1=active (Unspecified)
  [6:4] TX_IQMOD_GAIN_SEL — IQMOD gain selection
    0=m18p1dB (Gain -18.1dB); 1=m12p0dB (Gain -12.0dB); 2=m8p5dB (Gain -8.5dB); 3=m6p0dB (Gain -6.0dB); 4=m4p1dB (Gain -4.1dB); 5=m2p5dB (Gain -2.5dB); 6=m1p2dB (Gain -1.2dB); 7=0dB (Gain 0.0dB)
  [3:2] TX_IQMOD_BIAS_SEL_VCM — IQMOD input (ABB output) common-mode voltage VCM selection (default 3)
    0=0p75V (Unspecified); 1=0p8V (Unspecified); 2=0p85V (Unspecified); 3=0p9V (Unspecified)
  [1:0] TX_IQMOD_RFGM_SEL1 — IQMOD mixer gate bias voltage selection (default 3)
    0=VCM_plus_0p35V (VBIAS=VCM+350mV); 1=VCM_plus_0p375V (VBIAS=VCM+375mV); 2=VCM_plus_0p4V (VBIAS=VCM+400mV); 3=VCM_plus_0p425V (VBIAS=VCM+425mV)
0x870 TX_IQMOD_CTRL2 — TX IQMOD Control
  [2:0] TX_IQMOD_RFGM_SEL2 — TXLO BPF GM cell drive capability (default 4)
    0=min_drive (Unspecified); 7=max_drive (Unspecified)
0x874 TX_IQMOD_OFFSET — TX IQMOD Offset Measurement
  [18:16] TX_IQMOD_OFSMEAS_SEL_RMEAS — IQMOD pull-up resistor setting for LOFT compensation measurement. Value depends on ABB gain setting
    7=1880ohm (Unspecified); 6=940ohm (Unspecified); 5=627ohm (Unspecified); 4=470ohm (Unspecified); 3=376ohm (Unspecified); 2=313ohm (Unspecified); 1=269ohm (Unspecified); 0=235ohm (Unspecified)
  [12] TX_IQMOD_OFSMEASQ_INPUTSWITCH — IQMOD Q-branch offset measurement comparator input switch connection
    0=direct (Unspecified); 1=swapped (Unspecified)
  [8] TX_IQMOD_OFSMEASQ_PWRUP — IQMOD pwrup Q-branch offset measurement comparator
    0=disabled (Unspecified); 1=active (Unspecified)
  [4] TX_IQMOD_OFSMEASI_INPUTSWITCH — IQMOD I-branch offset measurement comparator input switch connection
    0=direct (Unspecified); 1=swapped (Unspecified)
  [0] TX_IQMOD_OFSMEASI_PWRUP — IQMOD pwrup I-branch offset measurement comparator
    0=disabled (Unspecified); 1=active (Unspecified)
0x878 TX_PPA_SEL — TX Front End configure
  [15:12] TX_ICOMBPPA_IBPSTUNE — Amount of constant current:2.5uA * (nb of ones)
    0=0uA (Unspecified); 1=2p5uA (Unspecified); 3=5uA (Unspecified); 7=7p5uA (Unspecified); 15=10uA (Unspecified)
  [11:8] TX_ICOMBPPA_ICGMTUNE — Amount of cgm current: 2.5uA * (nb of ones)
    values as TX_ICOMBPPA_IBPSTUNE
  [7] TX_RFSWI_HBSEL — Connect MHB balun secondary to HB PPA (NOT USED)
    0=disabled (Unspecified); 1=active (Unspecified)
  [6] TX_RFSWI_MBSEL — Connect MHB balun secondary to MB PPA
    0=disabled (Unspecified); 1=active (Unspecified)
  [5] TX_RFSWI_LBSEL — Connect LB balun secondary to LB PPA
    0=disabled (Unspecified); 1=active (Unspecified)
  [4] TX_RFSWI_VLBSEL — Connect LB balun secondary to VLB PPA (NOT USED)
    0=disabled (Unspecified); 1=active (Unspecified)
  [1] TX_PPALMB_CORE_SEL — Selects the used PPA core between LB and MB PPA
    0=LB_PPA (Lowband PPA selected); 1=MB_PPA (Midband PPA selected)
  [0] TX_PPALMB_SEL — Selects LB and MB PPA branch (default 0)
    0=LB_MB_branch (Midband or Low band branch selected); 1=Not used for Saana
0x87C TX_PPA_LMB_CTRL — TX PPA Low and Mid Band PPA control
  [9:8] TX_PPALMB_BIASMRATIO — Low/mid-band PPA bias block: GM cell mirroring ratio control
    {v}={v+2}to2 (Unspecified) (v=0..3)
  [5:4] TX_PPALMB_CASCOFFBIAS — Low/mid-band PPA bias block: GM cell cascode OFF bias voltage control (default 0)
    0=1100mV (Unspecified); 1=900mV (Unspecified); 2=700mV (Unspecified); 3=600mV (Unspecified)
  [1:0] TX_PPALMB_CASCBIAS — Low/mid-band PPA bias block: GM cell cascode ON bias voltage control (default 3)
    0=1057mV (Unspecified); 1=1084mV (Unspecified); 2=1210mV (Unspecified); 3=1427mV (Unspecified)
0x880 TX_PPA_LMB_GAIN — TX PPA Low and Mid Band PPA gain
  [31:28] TX_PPALMB_BIAS — Low/mid-band PPA bias block: GM cell bias current control
  [27] TX_PPALMB_SEL_MAINAUX — Low/mid-band PPA MAIN/AUX path pwrup selector
    0=main (Unspecified); 1=aux (Unspecified)
  [26:24] TX_PPALMB_GAINAUX — Low/mid-band PPA AUX path gain control (number of active AUX slices)
  [23:20] TX_PPALMB_CASCAUX — Low/midband PPA AUX path cascode gain control (cascode current splitting ratio)
  [18:16] TX_PPALMB_ROUT — Low/mid-band PPA ROUT control
  [12:8] TX_PPALMB_RFB — Low/mid-band PPA feedback resistor control
  [5:0] TX_PPALMB_GAINMAIN — Low/mid-band PPA MAIN path gain control (number of active MAIN slices)
0x884 TX_PPA_LMB_SPARE — TX PPA Low and Mid Band PPA control
  [6:4] TX_PPALMB_SPARE2 — Low/mid-band PPA spare controls
  [3:0] TX_PPALMB_SPARE — Low/mid-band PPA spare controls
0x888 TX_PPA_RESOTUNE_LB — TX PPA Resonators tuning at low band
  [18:16] TX_CTUNERLB_CTUNELOW — Low-band balun large tuning capacitor control (450MHz-650MHz bands)
  [12:8] TX_PPALB_CTUNEOUT — Low-band balun small tuning capacitor control (650MHz-915MHz bands)
  [4:0] TX_CTUNERLB_CTUNE — Low-band PPA output tuning capacitor control
0x88C TX_PPA_RESOTUNE_MHB — TX PPA Resonators' tuning at high band
  [18:16] TX_CTUNERMHB_CTUNELOW — Mid/high-band balun large tuning capacitor control (1427MHz-1710MHz bands)
  [12:8] TX_PPAMB_CTUNEOUT — Mid-band PPA output tuning capacitor control
  [4:0] TX_CTUNERMHB_CTUNE — Mid/high-band balun small tuning capacitor control (1710MHz-2570MHz bands)
0x8B0 TX_SPARE1 — TX spare reg
  [21] TX_TXFE_SPARE2_AVDD0V8INT — Spare bit
  [20] TX_TXFE_SPARE1_AVDD0V8INT — Spare bit
  [n+15] TX_TXFE_SPARE{n}_AVDDPPA1V5 (n=1..4) — Spare bit
  [13] TX_TXLO_SPARE2_LDOTXLO — Spare bit
  [12] TX_TXLO_SPARE1_LDOTXLO — Spare bit
  [n+8] TX_IQMOD_SPARE{n}_LDOCT (n=0..3) — Spare bit
  [n+3] TX_IQMOD_SPARE{n}_AVDD0V8INT (n=1..4) — Spare bit
  [n] TX_IQMOD_SPARE{n}_AVDD1V8 (n=0..3) — Spare bit
0x8B4 TX_LSFILT — TX LS filter control
  [4n-3:4n-4] TX_LSFILT{n} (n=1..4) — level shifter RC filter control
0x8D0 TX_WATE1 — TX test switch control
  [29:28] TX_DACLDO1V2_WATE_BIAS — Analog test mux control
  [26] TX_DACLDO1V2_NMOS_WATE — Analog test mux control
  [25:24] TX_DACLDO1V2_WATE — Analog test mux control
  [21:20] TX_LDOCT_BIAS_WATE — Analog test mux control
  [17:16] TX_LDOCT_WATE — Analog test mux control
  [13:12] TX_LDOTXLO_WATE — Analog test mux control
  [2] TX_AVDD0V8FILT_WATE — Analog test mux control
  [1] TX_SBUF_WATE — Analog test mux control
  [0] TX_IBPSR_WATE — Analog test mux control
0x8D4 TX_WATE2 — TX test switch control
  [14:7] TX_IQMOD_WATE — Analog test mux control
  [6:2] TX_TXABB_WATE — Analog test mux control
  [1:0] TX_DACLDO0V8_WATE — Analog test mux control
0x8D8 TX_WATE3 — TX test switch control
  [8] TX_AVDDPPA1V6_WATE — Analog test mux control
  [7] TX_AVDD1V8_WATE — Analog test mux control
  [6:5] TX_PPAMB_WATE — Analog test mux control
  [4:3] TX_PPALB_WATE — Analog test mux control
  [2] TX_PPAVBIAS_WATE — Analog test mux control
  [1] TX_ICGMPPA_TST — Analog test mux control
  [0] TX_ICGMPPA_WATE — Analog test mux control
0x8DC TX_DAC_TEST — TX test switch control
  [7:0] TX_TXDAC_WATE — Analog test mux control
0x8E0 TX_CALIB — TX test switch control
  [8] TX_CALIB_WATE_RSL — Enable R low to watb1
    1=activate (Unspecified); 0=no_effect (Unspecified)
  [7] TX_CALIB_WATE_RSH — Enable R high to watb1
    1=activate (Unspecified); 0=no_effect (Unspecified)
  [6] TX_CALIB_WATE_RVF — Enable watb0 to R
    1=activate (Unspecified); 0=no_effect (Unspecified)
  [5] TX_CALIB_WATE_RIM — Enable calib current to watb1
    1=activate (Unspecified); 0=no_effect (Unspecified)
  [4] TX_CALIB_WATE_RIF — Enable calib current to R
    1=activate (Unspecified); 0=no_effect (Unspecified)
  [3:0] TX_CALIB_CGMRTRIM — Value from TRIM to be stored here
0x8E4 TX_TMEAS — TX TMEAS control
  [28] TX_TMEAS_IBPSR_BOOST — Force ON bias start-up circuit
    1=activate (Unspecified); 0=no_effect (Unspecified)
  [27:24] TX_TMEAS_WATE1 — WATB1 configuration
    0=no_effect (Unspecified); 1=900mv_ntc_trim_voltage (Unspecified); 2=ts_pa_before_mux (Unspecified); 4=ts_pa_trim_voltage (Unspecified); 8=int_dio_offset_calib_V (Unspecified)
  [21:20] TX_TMEAS_WATE0 — WATB0 configuration
    0=no_effect (Unspecified); 1=temp_meas_ibps_10ua_trim_i (Unspecified); 2=int_dio_ibps_10ua (Unspecified)
  [17] TX_TMEAS_TSPAIREF_SEL — select DIODE mode for TS_PA
    1=activate (Unspecified); 0=no_effect (Unspecified)
  [16] TX_TMEAS_TSPAVREF_SEL — select NTC resistor mode for TS_PA
    1=activate (Unspecified); 0=no_effect (Unspecified)
  [13:8] TX_TMEAS_NTCTSPA_TRIM — Value from TRIM to be stored here
  [7:4] TX_TMEAS_NTCVREF_TRIM — Value from TRIM to be stored here
  [3:0] TX_TMEAS_IBPS_TRIM — Value from TRIM to be stored here
0xB00 TX_IQMOD_OFFSET_READ ro — TX IQMOD Offset Read comparator states
  [1] ODIG_TX_IQMOD_OFSMEASQ_COMPOUT — Q-branch comparator output
  [0] ODIG_TX_IQMOD_OFSMEASI_COMPOUT — I-branch comparator output

## Notices in the file
Copyright (c) 2010 - 2025, Nordic Semiconductor ASA
All rights reserved.
Redistribution and use in source and binary forms, with or without modification,
are permitted provided that the following conditions are met:
1. Redistributions of source code must retain the above copyright notice, this
list of conditions and the following disclaimer.
2. Redistributions in binary form, except as embedded into a Nordic
Semiconductor ASA integrated circuit in a product or a software update for
such product, must reproduce the above copyright notice, this list of
conditions and the following disclaimer in the documentation and/or other
materials provided with the distribution.
3. Neither the name of Nordic Semiconductor ASA nor the names of its
contributors may be used to endorse or promote products derived from this
software without specific prior written permission.
4. This software, with or without modification, must only be used with a
Nordic Semiconductor ASA integrated circuit.
5. Any software provided in binary form under this license must not be reverse
engineered, decompiled, modified and/or disassembled.
THIS SOFTWARE IS PROVIDED BY NORDIC SEMICONDUCTOR ASA "AS IS" AND ANY EXPRESS
OR IMPLIED WARRANTIES, INCLUDING, BUT NOT LIMITED TO, THE IMPLIED WARRANTIES
OF MERCHANTABILITY, NONINFRINGEMENT, AND FITNESS FOR A PARTICULAR PURPOSE ARE
DISCLAIMED. IN NO EVENT SHALL NORDIC SEMICONDUCTOR ASA OR CONTRIBUTORS BE
LIABLE FOR ANY DIRECT, INDIRECT, INCIDENTAL, SPECIAL, EXEMPLARY, OR
CONSEQUENTIAL DAMAGES (INCLUDING, BUT NOT LIMITED TO, PROCUREMENT OF SUBSTITUTE
GOODS OR SERVICES; LOSS OF USE, DATA, OR PROFITS; OR BUSINESS INTERRUPTION)
HOWEVER CAUSED AND ON ANY THEORY OF LIABILITY, WHETHER IN CONTRACT, STRICT
LIABILITY, OR TORT (INCLUDING NEGLIGENCE OR OTHERWISE) ARISING IN ANY WAY OUT
OF THE USE OF THIS SOFTWARE, EVEN IF ADVISED OF THE POSSIBILITY OF SUCH DAMAGE.
